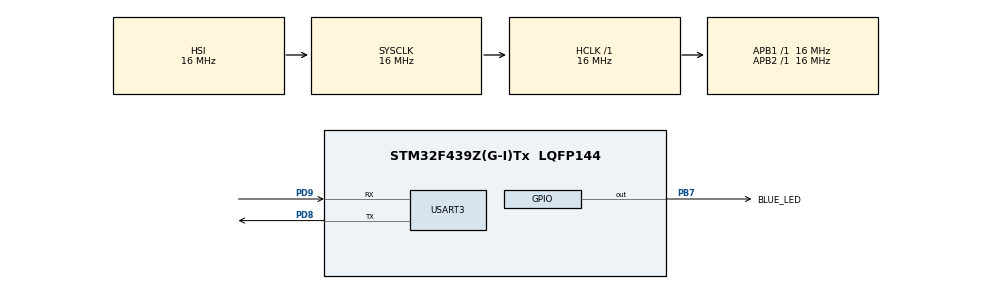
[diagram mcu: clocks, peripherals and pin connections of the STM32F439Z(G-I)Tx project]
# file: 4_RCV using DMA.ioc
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Dma.Request0=USART3_RX
Dma.USART3_RX.0.Direction=DMA_PERIPH_TO_MEMORY
Dma.USART3_RX.0.FIFOMode=DMA_FIFOMODE_DISABLE
Dma.USART3_RX.0.Instance=DMA1_Stream1
Dma.USART3_RX.0.MemDataAlignment=DMA_MDATAALIGN_BYTE
Dma.USART3_RX.0.MemInc=DMA_MINC_ENABLE
Dma.USART3_RX.0.Mode=DMA_CIRCULAR
Dma.USART3_RX.0.PeriphDataAlignment=DMA_PDATAALIGN_BYTE
Dma.USART3_RX.0.PeriphInc=DMA_PINC_DISABLE
Dma.USART3_RX.0.Priority=DMA_PRIORITY_LOW
Mcu.Family=STM32F4
Mcu.Name=STM32F439Z(G-I)Tx
Mcu.Package=LQFP144
NVIC.DMA1_Stream1_IRQn=true\:0\:0\:false\:false\:true\:false\:true\:true
NVIC.PriorityGroup=NVIC_PRIORITYGROUP_4
PB7.GPIO_Label=BLUE_LED
PB7.Signal=GPIO_Output
PD8.Mode=Asynchronous
PD8.Signal=USART3_TX
PD9.Mode=Asynchronous
PD9.Signal=USART3_RX
ProjectManager.HeapSize=0x200
ProjectManager.StackSize=0x400
ProjectManager.TargetToolchain=STM32CubeIDE
RCC.AHBFreq_Value=16000000
RCC.APB1Freq_Value=16000000
RCC.APB2Freq_Value=16000000
RCC.CortexFreq_Value=16000000
RCC.HSE_VALUE=25000000
RCC.HSI_VALUE=16000000
RCC.LSE_VALUE=32768
RCC.SYSCLKFreq_VALUE=16000000
RCC.VCOOutputFreq_Value=192000000
USART3.VirtualMode=VM_ASYNC
board=custom

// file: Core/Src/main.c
/* USER CODE BEGIN Header */
/**
  ******************************************************************************
  * @file           : main.c
  * @brief          : Main program body
  ******************************************************************************
  * @attention
  *
  * Copyright (c) 2024 STMicroelectronics.
  * All rights reserved.
  *
  * This software is licensed under terms that can be found in the LICENSE file
  * in the root directory of this software component.
  * If no LICENSE file comes with this software, it is provided AS-IS.
  *
  ******************************************************************************
  */
/* USER CODE END Header */
#include "main.h"
#include <string.h>

UART_HandleTypeDef huart3;
DMA_HandleTypeDef hdma_usart3_rx;

/* USER CODE BEGIN PV */
uint8_t RX_buffer[256];
uint8_t Main_buffer[4096];
uint8_t Half_counter = 0;
uint8_t Full_counter = 0;
uint8_t size;
uint8_t indx;
uint8_t HTC = 0;
uint8_t FTC = 0;
uint8_t isSet = 0;
/* USER CODE END PV */

void SystemClock_Config(void);
static void MX_GPIO_Init(void);
static void MX_DMA_Init(void);
static void MX_USART3_UART_Init(void);
/* USER CODE BEGIN PFP */

/* UART Receiving using DMA. DMA Mode: Normal
void HAL_UART_RxCpltCallback(UART_HandleTypeDef *huart){

	if(isSet == 0){
		size = ((RX_buffer[0]-48)*1000) + ((RX_buffer[1]-48)*100) + ((RX_buffer[2]-48)*10) + (RX_buffer[3]-48);
		HAL_UART_Receive_DMA(&huart3, RX_buffer, size);
		isSet = 1;
	}
	else if(isSet == 1){
		HAL_UART_Receive_DMA(&huart3, RX_buffer, 4);
		isSet = 0;
	}
	Full_counter++;
}

void HAL_UART_RxHalfCpltCallback(UART_HandleTypeDef *huart){
	Half_counter++;
}

*/

void HAL_UART_RxHalfCpltCallback(UART_HandleTypeDef *huart){
	if(isSet == 0){
		size = ((RX_buffer[0]-48)*1000) + ((RX_buffer[1]-48)*100) + ((RX_buffer[2]-48)*10) + (RX_buffer[3]-48);
		indx = 0;
		memcpy(Main_buffer+indx, RX_buffer+4, 124);
		memset(RX_buffer, '\0', 128);
		indx=+128;
		isSet = 1;
	}
	else {
		memcpy(Main_buffer+indx, RX_buffer, 128);
		memset(RX_buffer, '\0', 128);
		indx=+128;
	}
	Half_counter++;
	HTC = 1;
	FTC = 0;
}

void HAL_UART_RxCpltCallback(UART_HandleTypeDef *huart){

	memcpy(Main_buffer+indx, RX_buffer+128, 128);
	memset(RX_buffer+128, '\0', 128);
	Full_counter++;
}

/* USER CODE END PFP */

int main(void)
{

  /* MCU Configuration--------------------------------------------------------*/

  /* Reset of all peripherals, Initializes the Flash interface and the Systick. */
  HAL_Init();

  /* Configure the system clock */
  SystemClock_Config();

  /* Initialize all configured peripherals */
  MX_GPIO_Init();
  MX_DMA_Init();
  MX_USART3_UART_Init();
  HAL_UART_Receive_DMA(&huart3, RX_buffer, 256);
  /* Infinite loop */
  while (1)
  {
	  if(((size-indx)>0) && ((size-indx)<128)){
		  if(HTC == 1){
			  strcpy((char *)Main_buffer+indx, (char *)RX_buffer+128);
			  indx = size;
			  isSet = 0;
			  HTC = 0;
			  HAL_UART_DMAStop(&huart3);
			  HAL_UART_Receive_DMA(&huart3, RX_buffer, 256);
		  } else if(FTC == 1){
			  strcpy((char *)Main_buffer+indx, (char *)RX_buffer);
			  indx = size;
			  isSet = 0;
			  FTC = 0;
			  HAL_UART_DMAStop(&huart3);
			  HAL_UART_Receive_DMA(&huart3, RX_buffer, 256);
		  }
	  }else if((indx == size) && ((HTC=1)|| (FTC=1))){
		  isSet = 0;
		  HTC=0;
		  FTC=0;
		  HAL_UART_DMAStop(&huart3);
		  HAL_UART_Receive_DMA(&huart3, RX_buffer, 256);
	  }

  }
}

void SystemClock_Config(void)
{
  RCC_OscInitTypeDef RCC_OscInitStruct = {0};
  RCC_ClkInitTypeDef RCC_ClkInitStruct = {0};

  /** Configure the main internal regulator output voltage
  */
  __HAL_RCC_PWR_CLK_ENABLE();
  __HAL_PWR_VOLTAGESCALING_CONFIG(PWR_REGULATOR_VOLTAGE_SCALE3);

  /** Initializes the RCC Oscillators according to the specified parameters
  * in the RCC_OscInitTypeDef structure.
  */
  RCC_OscInitStruct.OscillatorType = RCC_OSCILLATORTYPE_HSI;
  RCC_OscInitStruct.HSIState = RCC_HSI_ON;
  RCC_OscInitStruct.HSICalibrationValue = RCC_HSICALIBRATION_DEFAULT;
  RCC_OscInitStruct.PLL.PLLState = RCC_PLL_NONE;
  if (HAL_RCC_OscConfig(&RCC_OscInitStruct) != HAL_OK)
  {
    Error_Handler();
  }

  /** Initializes the CPU, AHB and APB buses clocks
  */
  RCC_ClkInitStruct.ClockType = RCC_CLOCKTYPE_HCLK|RCC_CLOCKTYPE_SYSCLK
                              |RCC_CLOCKTYPE_PCLK1|RCC_CLOCKTYPE_PCLK2;
  RCC_ClkInitStruct.SYSCLKSource = RCC_SYSCLKSOURCE_HSI;
  RCC_ClkInitStruct.AHBCLKDivider = RCC_SYSCLK_DIV1;
  RCC_ClkInitStruct.APB1CLKDivider = RCC_HCLK_DIV1;
  RCC_ClkInitStruct.APB2CLKDivider = RCC_HCLK_DIV1;

  if (HAL_RCC_ClockConfig(&RCC_ClkInitStruct, FLASH_LATENCY_0) != HAL_OK)
  {
    Error_Handler();
  }
}

static void MX_USART3_UART_Init(void)
{

  huart3.Instance = USART3;
  huart3.Init.BaudRate = 115200;
  huart3.Init.WordLength = UART_WORDLENGTH_8B;
  huart3.Init.StopBits = UART_STOPBITS_1;
  huart3.Init.Parity = UART_PARITY_NONE;
  huart3.Init.Mode = UART_MODE_TX_RX;
  huart3.Init.HwFlowCtl = UART_HWCONTROL_NONE;
  huart3.Init.OverSampling = UART_OVERSAMPLING_16;
  if (HAL_UART_Init(&huart3) != HAL_OK)
  {
    Error_Handler();
  }

}

static void MX_DMA_Init(void)
{

  /* DMA controller clock enable */
  __HAL_RCC_DMA1_CLK_ENABLE();

  /* DMA interrupt init */
  /* DMA1_Stream1_IRQn interrupt configuration */
  HAL_NVIC_SetPriority(DMA1_Stream1_IRQn, 0, 0);
  HAL_NVIC_EnableIRQ(DMA1_Stream1_IRQn);

}

static void MX_GPIO_Init(void)
{
  GPIO_InitTypeDef GPIO_InitStruct = {0};

  /* GPIO Ports Clock Enable */
  __HAL_RCC_GPIOD_CLK_ENABLE();
  __HAL_RCC_GPIOB_CLK_ENABLE();

  /*Configure GPIO pin Output Level */
  HAL_GPIO_WritePin(BLUE_LED_GPIO_Port, BLUE_LED_Pin, GPIO_PIN_RESET);

  /*Configure GPIO pin : BLUE_LED_Pin */
  GPIO_InitStruct.Pin = BLUE_LED_Pin;
  GPIO_InitStruct.Mode = GPIO_MODE_OUTPUT_PP;
  GPIO_InitStruct.Pull = GPIO_NOPULL;
  GPIO_InitStruct.Speed = GPIO_SPEED_FREQ_LOW;
  HAL_GPIO_Init(BLUE_LED_GPIO_Port, &GPIO_InitStruct);

}

void Error_Handler(void)
{
  __disable_irq();
  while (1)
  {
  }
}
